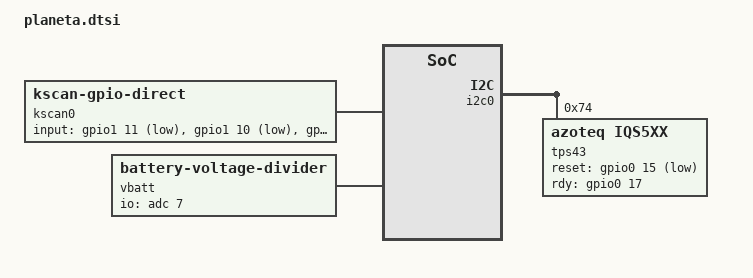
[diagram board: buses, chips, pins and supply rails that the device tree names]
#include <dt-bindings/zmk/matrix_transform.h>
#include <zephyr/dt-bindings/input/input-event-codes.h>
#include "planeta_layout.dtsi"

/ {
    chosen {
        zmk,kscan = &kscan0;
        zmk,physical-layout = &physical_layout;
        zmk,battery = &vbatt;
    };

    default_transform: keymap_transform_0 {
        compatible = "zmk,matrix-transform";
        columns = <2>;
        rows = <1>;
        map = <
        RC(0,3) RC(0,2)
        >;
    };

    kscan0: kscan {
        compatible = "zmk,kscan-gpio-direct";
        wakeup-source;
        input-gpios
        = <&gpio1 11 (GPIO_ACTIVE_LOW | GPIO_PULL_UP)>
        , <&gpio1 10 (GPIO_ACTIVE_LOW | GPIO_PULL_UP)>
        , <&gpio0  3 (GPIO_ACTIVE_LOW | GPIO_PULL_UP)>
        , <&gpio0 28 (GPIO_ACTIVE_LOW | GPIO_PULL_UP)>
        ;
    };

    vbatt: vbatt {
        status = "okay";
        compatible = "zmk,battery-voltage-divider";
        io-channels = <&adc 7>;
        output-ohms = <1564000>;
        full-ohms = <(806000 + 1564000)>;
    };

    tps43_listener: tps43_listener {
        compatible = "zmk,input-listener";
        status = "ok";
        device = <&tps43>;
    };

    split_inputs {
        #address-cells = <1>;
        #size-cells = <0>;

        trackball_split: trackball_split@0 {
            compatible = "zmk,input-split";
            reg = <0>;
            status = "disabled";
        };
    };
};

&i2c0 {
    status = "okay";
    tps43: iqs5xx@74 {
        status = "okay";
        compatible = "azoteq,iqs5xx";
        reg = <0x74>;

        reset-gpios = <&gpio0 15 GPIO_ACTIVE_LOW>;
        rdy-gpios = <&gpio0 17 GPIO_ACTIVE_HIGH>;

        /*
         * Potentially non-exhaustive list of configuration options.
         * See: dts/bindings/input/azoteq,iqs5xx-common.yaml for a full list.
         */
        one-finger-tap;
        press-and-hold;
        press-and-hold-time = <250>;
        two-finger-tap;

        scroll;
        natural-scroll-y;
        natural-scroll-x;

        bottom-beta = <5>;
        stationary-threshold = <5>;

        switch-xy;
    };
};
